# A31C15x register map
Vendor: ABOV Semiconductor Co., Ltd.; File version: 1.0
CPU: CM0PLUS r0p1, little endian, no MPU, no FPU, VTOR, 2 interrupt priority bits
Registers are 32-bit, read-write, reset 0x0 unless marked. A register's access mark holds for its fields unless they carry their own. Offsets are from the block's base; [hi:lo] are bit positions; {n}, {i} and the like mark numbered series.

## TIMER0 — TIMER COUNTER 0
Base 0x40003000
Same registers: TIMER{n} {0x40003000+0x40*n} (n=1..9)
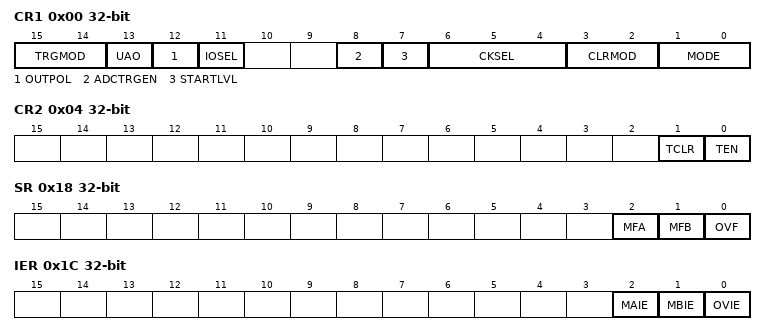
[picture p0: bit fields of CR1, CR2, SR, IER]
0x00 CR1 — Timer / counter n control register 1
  [15:14] TRGMOD — ADC trigger mode selection
    0=GRA (GRA Value Trigger Mode (Normal Mode)); 2=TRGPNT (TRGPNT Value Trigger Mode); 3=GRA_TRGPNT (GRA, TRGPNT Value Both Trigger Mode)
  [13] UAO — GRA / GRB update mode selection
    0=Next_Period (Write Value Apply to next period); 1=Current_Period (Write value apply to current period)
  [12] OUTPOL — Timer output polarity
    0=Normal Output; 1=Polarity (Polairty Output)
  [11] IOSEL — Timer output polarity
    0=Input (Timer Input Port Setting); 1=Output (Timer Output Port Setting)
  [8] ADCTRGEN — Whether or not to use the timer as an ADC trigger source
    0=No_Used; 1=Used
  [7] STARTLVL — Starting output value in periodic / PWM / one-shot modes
    0=Low (Output Start Low); 1=High (Output Start High)
  [6:4] CKSEL — Counter clock source selection
    0=PCLK/2 (Counter Clock is PCLK/2); 1=PCLK/4 (Counter Clock is PCLK/4); 2=PCLK/16 (Counter Clock is PCLK/16); 3=PCLK/64 (Counter Clock is PCLK/64); 4=EXT0(MCCR3) (Counter Clock is EXT0(MCCR3)); 6=TnIO (Counter Clock is TnIO (input pin))
  [3:2] CLRMOD — Clear mode selection in capture mode
    0=Rising Edge Clear Mode; 1=Falling Edge Clear Mode; 2=Both (Rising/Falling Edge Clear Mode); 3=Not Clear Mode
  [1:0] MODE — Timer operation mode control
    0=Interval (Timer is Interval Mode); 1=PWM (Timer is PWM Mode); 2=One-shot (Timer is One-Shot Mode); 3=Capture (Timer is Capture Mode)
0x04 CR2 — Timer / counter n control register 2
  [1] TCLR wo — Clearing of the timer count register
  [0] TEN — Whether to enable or disable the timer
    0=Disable (Timer Disable); 1=Enable (Timer Enable)
0x08 PRS — Timer / counter n prescaler register
  [9:0] PRS — Counter Clock Prescaler Value, TCLK=CLOCK_IN/(PRS+1)
0x0C GRA — Timer / counter n general data register A
  [15:0] GRA — Timer general register A
0x10 GRB — Timer / counter n general data register B
  [15:0] GRB — Timer general register B
0x14 CNT — Timer / counter n count register
  [15:0] CNT — Timer count value
0x18 SR — Timer / counter n status register
  [2] MFA — TIMERn_GRA match flag
  [1] MFB — TIMERn_GRB match flag
  [0] OVF — Counter overflow flag
0x1C IER — Timer / counter n interrupt enable register
  [2] MAIE — Whether to enable or disable the TIMERn_GRA match interrupt
  [1] MBIE — Whether to enable or disable the TIMERn_GRB match interrupt
  [0] OVIE — Whether to enable or disable the counter overflow interrupt
0x20 TRGPNT — Timer / counter n trigger point register
  [15:0] TRGPNT — Timer trigger point value
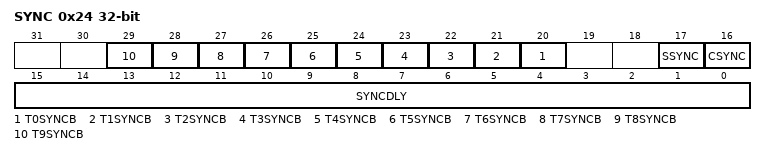
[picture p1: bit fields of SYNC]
0x24 SYNC — Timer / counter n sync configuration register
  [n+20] T{n}SYNCB (n=0..9) — Synchronization settings to Timer {n}
    0=Disable (SYNC Disable); 1=Enable (SYNC Enable)
  [17] SSYNC — Synchronizes other synchronization timer to start counter
    0=Disable (SYNC Disable); 1=Enable (SYNC Enable)
  [16] CSYNC — Synchronizes other synchronization timer to clear counter
    0=Disable (SYNC Disable); 1=Enable (SYNC Enable)
  [15:0] SYNCDLY — SYNC delay start count value setting bit(based on the master counter)

## FRT — Free Run Timer
Base 0x40000600
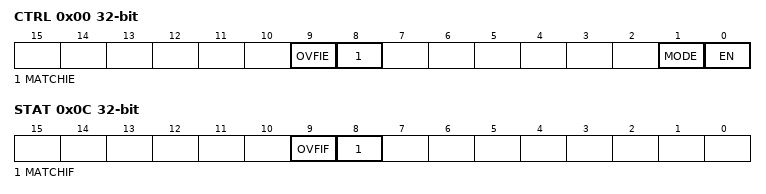
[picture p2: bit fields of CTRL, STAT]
0x00 CTRL — FRT control register
  [9] OVFIE — Whether to enable or disable the FRT counter overflow interrupt in Free-run timer mode (MODE = 0)
    0=Disable (Interrupt Disable); 1=Enable (Interrupt Enable)
  [8] MATCHIE — Whether to enable or disable the FRT counter match interrupt in Periodic timer mode (MODE = 1)
    0=Disable (Interrupt Disable); 1=Enable (Interrupt Enable)
  [1] MODE — FRT mode selection
    0=Free-Run_Timer; 1=Periodic_Timer
  [0] EN — Whether to enable or disable the FRT
    0=Disable (FRT Disable); 1=Enable (FRT Enable)
0x04 MCNT reset 0xFFFFFFFF — FRT match counter register
  [31:0] MCNT — FRTs match counter value
0x08 CNT — FRT counter register
  [31:0] CNT — FRT count data
0x0C STAT — FRT status register
  [9] OVFIF — FRT counter overflow interrupt flag
  [8] MATCHIF — FRT counter match interrupt flag
